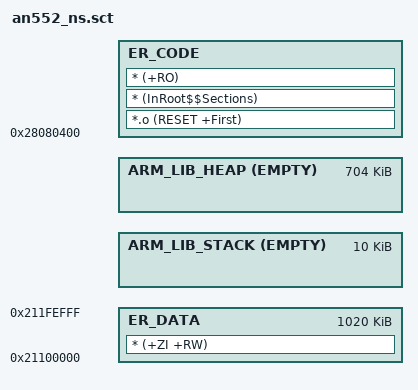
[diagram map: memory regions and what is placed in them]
/* Copyright 2023 Arm Limited and/or its affiliates
 * <open-source-office@arm.com>
 * SPDX-License-Identifier: Apache-2.0
 */

LR_CODE (0x28000000 + ((((0) + (0x80000)) + (0x400)))) {
    ER_CODE (0x28000000 + ((((0) + (0x80000)) + (0x400)))) { ;(((0x300000) - (0x400) - (0xC00))) {
        *.o (RESET +First)
        * (InRoot$$Sections)
        * (+RO)
    }

    /* The last 0x1000 bytes are reserved for the provisioning bundle */
    ER_DATA (0x21100000) (0x00100000 - 0x1000) {
        * (+ZI +RW)
    }

    ARM_LIB_STACK +0 ALIGN 32 EMPTY (0x0002800) {
    }
    ARM_LIB_HEAP +0 ALIGN 8 EMPTY (0x00b0000) {
    }
}
